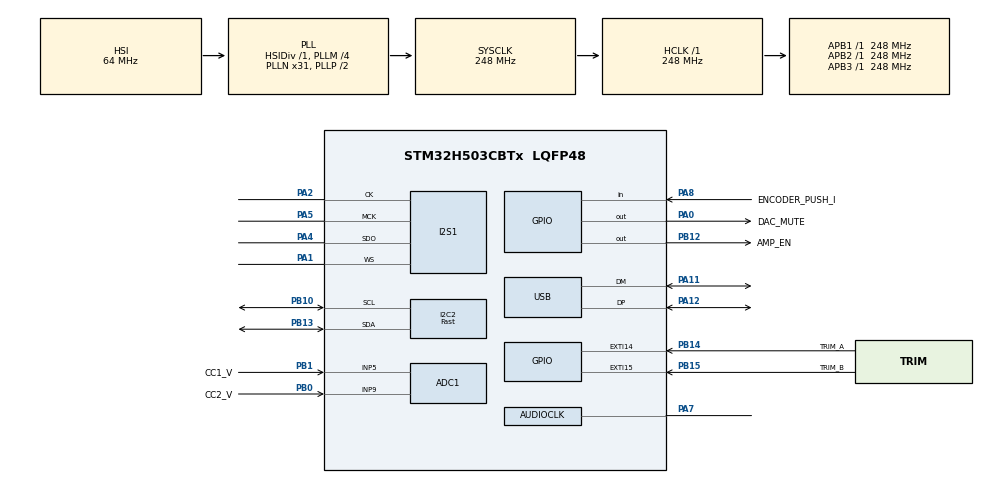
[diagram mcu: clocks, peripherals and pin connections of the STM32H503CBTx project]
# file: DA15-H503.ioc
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ADC1.Channel-1\#ChannelRegularConversion=ADC_CHANNEL_5
ADC1.Channel-2\#ChannelRegularConversion=ADC_CHANNEL_9
ADC1.MonitoredBy-1\#ChannelRegularConversion=__NULL
ADC1.MonitoredBy-2\#ChannelRegularConversion=__NULL
ADC1.NbrOfConversion=2
ADC1.NbrOfConversionFlag=1
ADC1.OffsetNumber-1\#ChannelRegularConversion=ADC_OFFSET_NONE
ADC1.OffsetNumber-2\#ChannelRegularConversion=ADC_OFFSET_NONE
ADC1.Rank-1\#ChannelRegularConversion=1
ADC1.Rank-2\#ChannelRegularConversion=2
ADC1.SamplingTime-1\#ChannelRegularConversion=ADC_SAMPLETIME_92CYCLES_5
ADC1.SamplingTime-2\#ChannelRegularConversion=ADC_SAMPLETIME_92CYCLES_5
ADC1.master=1
BOOTPATH.BootPathName=LEGACY
BOOTPATH.UserSelectedBootPath=LEGACY
CORTEX_M33_NS.AccessPermission-Cortex_Memory_Protection_Unit_Region0_Settings=MPU_REGION_ALL_RO
CORTEX_M33_NS.BaseAddress-Cortex_Memory_Protection_Unit_Region0_Settings=0x08FFF800
CORTEX_M33_NS.DisableExec-Cortex_Memory_Protection_Unit_Region0_Settings=MPU_INSTRUCTION_ACCESS_DISABLE
CORTEX_M33_NS.Enable-Cortex_Memory_Protection_Unit_Region0_Settings=MPU_REGION_ENABLE
CORTEX_M33_NS.LimitAddress-Cortex_Memory_Protection_Unit_Region0_Settings=0x08FFFFFF
CORTEX_M33_NS.MPU_Control=MPU_PRIVILEGED_DEFAULT
CORTEX_M33_NS.Memorytype0-Cortex_Memory_Protection_Unit_Attributes0_OTP_RO_AREAS_Settings=MPU_DEVICE
CORTEX_M33_NS.Number-Cortex_Memory_Protection_Unit_Region0_OTP_RO_AREAS_Settings=MPU_REGION_NUMBER0
CORTEX_M33_NS.Number-Cortex_Memory_Protection_Unit_Region0_Settings=MPU_REGION_NUMBER0
CORTEX_M33_NS.default_mode_Activation=1
GPDMA1.CIRCULARMODE_GPDMACH0=ENABLE
GPDMA1.DESTDATAWIDTH_GPDMACH0=DMA_DEST_DATAWIDTH_WORD
GPDMA1.DIRECTION_GPDMACH0=DMA_MEMORY_TO_PERIPH
GPDMA1.IPHANDLE_GPDMACH0-SIMPLEREQUEST_GPDMACH0=__NULL
GPDMA1.PRIORITY_LL_CIRCULAR_GPDMACH0=DMA_LOW_PRIORITY_HIGH_WEIGHT
GPDMA1.REQUEST_GPDMACH0=GPDMA1_REQUEST_SPI1_TX
GPDMA1.SRCDATAWIDTH_GPDMACH0=DMA_SRC_DATAWIDTH_WORD
GPDMA1.SRCINC_GPDMACH0=DMA_SINC_INCREMENTED
GPDMA2.DIRECTION_GPDMACH0=DMA_MEMORY_TO_PERIPH
GPDMA2.IPHANDLE_GPDMACH0-SIMPLEREQUEST_GPDMACH0=__NULL
GPDMA2.REQUEST_GPDMACH0=GPDMA2_REQUEST_I2C2_TX
GPDMA2.SRCINC_GPDMACH0=DMA_SINC_INCREMENTED
I2C2.I2C_Speed_Mode=I2C_Fast
I2C2.Speed=400
I2C2.Timing=0x20802C97
I2S1.AudioFreq=I2S_AUDIOFREQ_48K
I2S1.Data24BitAlignment=I2S_DATA_24BIT_ALIGNMENT_LEFT
I2S1.DataFormat=I2S_DATAFORMAT_24B
I2S1.ErrorAudioFreq=0.0 %
I2S1.Instance=SPI$Index
I2S1.RealAudioFreq=48.0 KHz
Mcu.Family=STM32H5
Mcu.Name=STM32H503CBTx
Mcu.Package=LQFP48
NVIC.EXTI14_IRQn=true\:0\:0\:false\:false\:true\:true\:true\:true
NVIC.EXTI15_IRQn=true\:0\:0\:false\:false\:true\:true\:true\:true
NVIC.GPDMA1_Channel0_IRQn=true\:0\:0\:false\:false\:true\:false\:true\:true
NVIC.GPDMA2_Channel0_IRQn=true\:0\:0\:false\:false\:true\:false\:true\:true
NVIC.I2C2_ER_IRQn=true\:0\:0\:false\:false\:true\:true\:true\:true
NVIC.I2C2_EV_IRQn=true\:0\:0\:false\:false\:true\:true\:true\:true
NVIC.PriorityGroup=NVIC_PRIORITYGROUP_4
NVIC.USB_DRD_FS_IRQn=true\:0\:0\:false\:false\:true\:true\:true\:true
PA0.GPIO_Label=DAC_MUTE
PA0.Signal=GPIO_Output
PA1.Mode=Half_Duplex_Master_Tx
PA1.Signal=I2S1_WS
PA11.Mode=Device
PA11.Signal=USB_DM
PA12.Mode=Device
PA12.Signal=USB_DP
PA2.Mode=Half_Duplex_Master_Tx
PA2.Signal=I2S1_CK
PA4.Mode=Half_Duplex_Master_Tx
PA4.Signal=I2S1_SDO
PA5.Mode=Master_Clock_Activated
PA5.Signal=I2S1_MCK
PA7.Mode=Audio_ClockInSAI1
PA7.Signal=AUDIOCLK
PA8.GPIO_Label=ENCODER_PUSH_I
PA8.Signal=GPIO_Input
PB0.GPIO_Label=CC2_V
PB0.Signal=ADCx_INP9
PB1.GPIO_Label=CC1_V
PB1.Signal=ADCx_INP5
PB10.Mode=I2C
PB10.Signal=I2C2_SCL
PB12.GPIO_Label=AMP_EN
PB12.PinState=GPIO_PIN_RESET
PB12.Signal=GPIO_Output
PB13.Mode=I2C
PB13.Signal=I2C2_SDA
PB14.GPIO_Label=TRIM_A
PB14.GPIO_ModeDefaultEXTI=GPIO_MODE_IT_RISING_FALLING
PB14.GPIO_PuPd=GPIO_PULLUP
PB14.Signal=GPXTI14
PB15.GPIO_Label=TRIM_B
PB15.GPIO_ModeDefaultEXTI=GPIO_MODE_IT_RISING_FALLING
PB15.GPIO_PuPd=GPIO_PULLUP
PB15.Signal=GPXTI15
ProjectManager.HeapSize=0x200
ProjectManager.StackSize=0x400
ProjectManager.TargetToolchain=CMake
RCC.ADCFreq_Value=248000000
RCC.AHBFreq_Value=248000000
RCC.APB1Freq_Value=248000000
RCC.APB1TimFreq_Value=248000000
RCC.APB2Freq_Value=248000000
RCC.APB2TimFreq_Value=248000000
RCC.APB3Freq_Value=248000000
RCC.CSI_VALUE=4000000
RCC.CortexFreq_Value=248000000
RCC.EPOD_VALUE=64000000
RCC.EXTERNAL_CLOCK_VALUE=24576000
RCC.HCLKFreq_Value=248000000
RCC.HSE_VALUE=25000000
RCC.HSI48_VALUE=48000000
RCC.HSIDiv=RCC_HSI_DIV1
RCC.HSI_VALUE=64000000
RCC.LSE_VALUE=32768
RCC.LSIRC_VALUE=32000
RCC.PLL2FRACN=0
RCC.PLL2P=7
RCC.PLLFRACN=0
RCC.PLLM=4
RCC.PLLN=31
RCC.PLLSourceVirtual=RCC_PLL1_SOURCE_HSI
RCC.SPI1CLockSelection=RCC_SPI1CLKSOURCE_PIN
RCC.SYSCLKFreq_VALUE=248000000
RCC.SYSCLKSource=RCC_SYSCLKSOURCE_PLLCLK
RCC.USBFreq_Value=48000000
RCC.VCOOutputFreq_Value=496000000
SH.ADCx_INP5.0=ADC1_INP5,IN5-Single-Ended
SH.ADCx_INP9.0=ADC1_INP9,IN9-Single-Ended
USB.Sof_enable-Device=DISABLE
USB.VirtualMode=Device_Only
VP_BOOTPATH_VS_BOOTPATH.Mode=BP_Activate
VP_CORTEX_M33_NS_VS_Hclk.Mode=Hclk_Mode
VP_GPDMA1_VS_GPDMACH0.Mode=SIMPLEREQUEST_GPDMACH0
VP_GPDMA2_VS_GPDMACH0.Mode=SIMPLEREQUEST_GPDMACH0
VP_ICACHE_VS_ICACHE.Mode=DefaultMode
VP_MEMORYMAP_VS_MEMORYMAP.Mode=CurAppReg
VP_PWR_VS_LPOM.Mode=PowerOptimisation
VP_PWR_VS_SECSignals.Mode=Security/Privilege
VP_RCC_USB.Mode=CRS SYNC Source USB
board=custom

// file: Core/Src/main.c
/* USER CODE BEGIN Header */
/**
  ******************************************************************************
  * @file           : main.c
  * @brief          : Main program body
  ******************************************************************************
  * @attention
  *
  * Copyright (c) 2026 STMicroelectronics.
  * All rights reserved.
  *
  * This software is licensed under terms that can be found in the LICENSE file
  * in the root directory of this software component.
  * If no LICENSE file comes with this software, it is provided AS-IS.
  *
  ******************************************************************************
  */
/* USER CODE END Header */
#include "main.h"

/* USER CODE BEGIN Includes */
#include "app.h"
#include "fault.h"
#include "SEGGER_RTT.h"
/* USER CODE END Includes */

ADC_HandleTypeDef hadc1;

I2C_HandleTypeDef hi2c2;
DMA_HandleTypeDef handle_GPDMA2_Channel0;

I2S_HandleTypeDef hi2s1;
DMA_NodeTypeDef Node_GPDMA1_Channel0;
DMA_QListTypeDef List_GPDMA1_Channel0;
DMA_HandleTypeDef handle_GPDMA1_Channel0;

PCD_HandleTypeDef hpcd_USB_DRD_FS;

void SystemClock_Config(void);
static void MPU_Config(void);
static void MX_GPIO_Init(void);
static void MX_GPDMA1_Init(void);
static void MX_GPDMA2_Init(void);
static void MX_ADC1_Init(void);
static void MX_I2C2_Init(void);
static void MX_I2S1_Init(void);
static void MX_USB_PCD_Init(void);
static void MX_ICACHE_Init(void);

int main(void)
{

  /* MCU Configuration--------------------------------------------------------*/

  /* MPU Configuration--------------------------------------------------------*/
  MPU_Config();

  /* Reset of all peripherals, Initializes the Flash interface and the Systick. */
  HAL_Init();

  /* Configure the system clock */
  SystemClock_Config();

  /* Initialize all configured peripherals */
  MX_GPIO_Init();
  MX_GPDMA1_Init();
  MX_GPDMA2_Init();
  MX_ADC1_Init();
  MX_I2C2_Init();
  MX_I2S1_Init();
  MX_USB_PCD_Init();
  MX_ICACHE_Init();
  /* USER CODE BEGIN 2 */
  app_init();
  /* USER CODE END 2 */

  /* Infinite loop */
  while (1)
  {

    /* USER CODE BEGIN 3 */
    app_loop();
  }
  /* USER CODE END 3 */
}

void SystemClock_Config(void)
{
  RCC_OscInitTypeDef RCC_OscInitStruct = {0};
  RCC_ClkInitTypeDef RCC_ClkInitStruct = {0};
  RCC_CRSInitTypeDef RCC_CRSInitStruct = {0};

  /** Configure the main internal regulator output voltage
  */
  __HAL_PWR_VOLTAGESCALING_CONFIG(PWR_REGULATOR_VOLTAGE_SCALE0);

  while(!__HAL_PWR_GET_FLAG(PWR_FLAG_VOSRDY)) {}

  /** Initializes the RCC Oscillators according to the specified parameters
  * in the RCC_OscInitTypeDef structure.
  */
  RCC_OscInitStruct.OscillatorType = RCC_OSCILLATORTYPE_HSI48|RCC_OSCILLATORTYPE_HSI;
  RCC_OscInitStruct.HSIState = RCC_HSI_ON;
  RCC_OscInitStruct.HSIDiv = RCC_HSI_DIV1;
  RCC_OscInitStruct.HSICalibrationValue = RCC_HSICALIBRATION_DEFAULT;
  RCC_OscInitStruct.HSI48State = RCC_HSI48_ON;
  RCC_OscInitStruct.PLL.PLLState = RCC_PLL_ON;
  RCC_OscInitStruct.PLL.PLLSource = RCC_PLL1_SOURCE_HSI;
  RCC_OscInitStruct.PLL.PLLM = 4;
  RCC_OscInitStruct.PLL.PLLN = 31;
  RCC_OscInitStruct.PLL.PLLP = 2;
  RCC_OscInitStruct.PLL.PLLQ = 2;
  RCC_OscInitStruct.PLL.PLLR = 2;
  RCC_OscInitStruct.PLL.PLLRGE = RCC_PLL1_VCIRANGE_3;
  RCC_OscInitStruct.PLL.PLLVCOSEL = RCC_PLL1_VCORANGE_WIDE;
  RCC_OscInitStruct.PLL.PLLFRACN = 0;
  if (HAL_RCC_OscConfig(&RCC_OscInitStruct) != HAL_OK)
  {
    Error_Handler();
  }

  /** Initializes the CPU, AHB and APB buses clocks
  */
  RCC_ClkInitStruct.ClockType = RCC_CLOCKTYPE_HCLK|RCC_CLOCKTYPE_SYSCLK
                              |RCC_CLOCKTYPE_PCLK1|RCC_CLOCKTYPE_PCLK2
                              |RCC_CLOCKTYPE_PCLK3;
  RCC_ClkInitStruct.SYSCLKSource = RCC_SYSCLKSOURCE_PLLCLK;
  RCC_ClkInitStruct.AHBCLKDivider = RCC_SYSCLK_DIV1;
  RCC_ClkInitStruct.APB1CLKDivider = RCC_HCLK_DIV1;
  RCC_ClkInitStruct.APB2CLKDivider = RCC_HCLK_DIV1;
  RCC_ClkInitStruct.APB3CLKDivider = RCC_HCLK_DIV1;

  if (HAL_RCC_ClockConfig(&RCC_ClkInitStruct, FLASH_LATENCY_5) != HAL_OK)
  {
    Error_Handler();
  }

  /** Enable the CRS APB clock
  */
  __HAL_RCC_CRS_CLK_ENABLE();

  /** Configures CRS
  */
  RCC_CRSInitStruct.Prescaler = RCC_CRS_SYNC_DIV1;
  RCC_CRSInitStruct.Source = RCC_CRS_SYNC_SOURCE_USB;
  RCC_CRSInitStruct.Polarity = RCC_CRS_SYNC_POLARITY_RISING;
  RCC_CRSInitStruct.ReloadValue = __HAL_RCC_CRS_RELOADVALUE_CALCULATE(48000000,1000);
  RCC_CRSInitStruct.ErrorLimitValue = 34;
  RCC_CRSInitStruct.HSI48CalibrationValue = 32;

  HAL_RCCEx_CRSConfig(&RCC_CRSInitStruct);

  /** Configure the programming delay
  */
  __HAL_FLASH_SET_PROGRAM_DELAY(FLASH_PROGRAMMING_DELAY_2);
}

static void MX_ADC1_Init(void)
{

  ADC_ChannelConfTypeDef sConfig = {0};

  /** Common config
  */
  hadc1.Instance = ADC1;
  hadc1.Init.ClockPrescaler = ADC_CLOCK_ASYNC_DIV8;
  hadc1.Init.Resolution = ADC_RESOLUTION_12B;
  hadc1.Init.DataAlign = ADC_DATAALIGN_RIGHT;
  hadc1.Init.ScanConvMode = ADC_SCAN_ENABLE;
  hadc1.Init.EOCSelection = ADC_EOC_SINGLE_CONV;
  hadc1.Init.LowPowerAutoWait = DISABLE;
  hadc1.Init.ContinuousConvMode = DISABLE;
  hadc1.Init.NbrOfConversion = 2;
  hadc1.Init.DiscontinuousConvMode = DISABLE;
  hadc1.Init.ExternalTrigConv = ADC_SOFTWARE_START;
  hadc1.Init.ExternalTrigConvEdge = ADC_EXTERNALTRIGCONVEDGE_NONE;
  hadc1.Init.DMAContinuousRequests = DISABLE;
  hadc1.Init.SamplingMode = ADC_SAMPLING_MODE_NORMAL;
  hadc1.Init.Overrun = ADC_OVR_DATA_PRESERVED;
  hadc1.Init.OversamplingMode = DISABLE;
  if (HAL_ADC_Init(&hadc1) != HAL_OK)
  {
    Error_Handler();
  }

  /** Configure Regular Channel
  */
  sConfig.Channel = ADC_CHANNEL_5;
  sConfig.Rank = ADC_REGULAR_RANK_1;
  sConfig.SamplingTime = ADC_SAMPLETIME_92CYCLES_5;
  sConfig.SingleDiff = ADC_SINGLE_ENDED;
  sConfig.OffsetNumber = ADC_OFFSET_NONE;
  sConfig.Offset = 0;
  if (HAL_ADC_ConfigChannel(&hadc1, &sConfig) != HAL_OK)
  {
    Error_Handler();
  }

  /** Configure Regular Channel
  */
  sConfig.Channel = ADC_CHANNEL_9;
  sConfig.Rank = ADC_REGULAR_RANK_2;
  if (HAL_ADC_ConfigChannel(&hadc1, &sConfig) != HAL_OK)
  {
    Error_Handler();
  }

}

static void MX_GPDMA1_Init(void)
{

  /* Peripheral clock enable */
  __HAL_RCC_GPDMA1_CLK_ENABLE();

  /* GPDMA1 interrupt Init */
    HAL_NVIC_SetPriority(GPDMA1_Channel0_IRQn, 0, 0);
    HAL_NVIC_EnableIRQ(GPDMA1_Channel0_IRQn);

}

static void MX_GPDMA2_Init(void)
{

  /* Peripheral clock enable */
  __HAL_RCC_GPDMA2_CLK_ENABLE();

  /* GPDMA2 interrupt Init */
    HAL_NVIC_SetPriority(GPDMA2_Channel0_IRQn, 0, 0);
    HAL_NVIC_EnableIRQ(GPDMA2_Channel0_IRQn);

}

static void MX_I2C2_Init(void)
{

  hi2c2.Instance = I2C2;
  hi2c2.Init.Timing = 0x20802C97;
  hi2c2.Init.OwnAddress1 = 0;
  hi2c2.Init.AddressingMode = I2C_ADDRESSINGMODE_7BIT;
  hi2c2.Init.DualAddressMode = I2C_DUALADDRESS_DISABLE;
  hi2c2.Init.OwnAddress2 = 0;
  hi2c2.Init.OwnAddress2Masks = I2C_OA2_NOMASK;
  hi2c2.Init.GeneralCallMode = I2C_GENERALCALL_DISABLE;
  hi2c2.Init.NoStretchMode = I2C_NOSTRETCH_DISABLE;
  if (HAL_I2C_Init(&hi2c2) != HAL_OK)
  {
    Error_Handler();
  }

  /** Configure Analogue filter
  */
  if (HAL_I2CEx_ConfigAnalogFilter(&hi2c2, I2C_ANALOGFILTER_ENABLE) != HAL_OK)
  {
    Error_Handler();
  }

  /** Configure Digital filter
  */
  if (HAL_I2CEx_ConfigDigitalFilter(&hi2c2, 0) != HAL_OK)
  {
    Error_Handler();
  }

}

static void MX_I2S1_Init(void)
{

  hi2s1.Instance = SPI1;
  hi2s1.Init.Mode = I2S_MODE_MASTER_TX;
  hi2s1.Init.Standard = I2S_STANDARD_PHILIPS;
  hi2s1.Init.DataFormat = I2S_DATAFORMAT_24B;
  hi2s1.Init.MCLKOutput = I2S_MCLKOUTPUT_ENABLE;
  hi2s1.Init.AudioFreq = I2S_AUDIOFREQ_48K;
  hi2s1.Init.CPOL = I2S_CPOL_LOW;
  hi2s1.Init.FirstBit = I2S_FIRSTBIT_MSB;
  hi2s1.Init.WSInversion = I2S_WS_INVERSION_DISABLE;
  hi2s1.Init.Data24BitAlignment = I2S_DATA_24BIT_ALIGNMENT_LEFT;
  hi2s1.Init.MasterKeepIOState = I2S_MASTER_KEEP_IO_STATE_DISABLE;
  if (HAL_I2S_Init(&hi2s1) != HAL_OK)
  {
    Error_Handler();
  }

}

static void MX_ICACHE_Init(void)
{

  /** Enable instruction cache (default 2-ways set associative cache)
  */
  if (HAL_ICACHE_Enable() != HAL_OK)
  {
    Error_Handler();
  }

}

static void MX_USB_PCD_Init(void)
{

  hpcd_USB_DRD_FS.Instance = USB_DRD_FS;
  hpcd_USB_DRD_FS.Init.dev_endpoints = 8;
  hpcd_USB_DRD_FS.Init.speed = USBD_FS_SPEED;
  hpcd_USB_DRD_FS.Init.phy_itface = PCD_PHY_EMBEDDED;
  hpcd_USB_DRD_FS.Init.Sof_enable = DISABLE;
  hpcd_USB_DRD_FS.Init.low_power_enable = DISABLE;
  hpcd_USB_DRD_FS.Init.lpm_enable = DISABLE;
  hpcd_USB_DRD_FS.Init.battery_charging_enable = DISABLE;
  hpcd_USB_DRD_FS.Init.vbus_sensing_enable = DISABLE;
  hpcd_USB_DRD_FS.Init.bulk_doublebuffer_enable = DISABLE;
  hpcd_USB_DRD_FS.Init.iso_singlebuffer_enable = DISABLE;
  if (HAL_PCD_Init(&hpcd_USB_DRD_FS) != HAL_OK)
  {
    Error_Handler();
  }

}

static void MX_GPIO_Init(void)
{
  GPIO_InitTypeDef GPIO_InitStruct = {0};

  /* GPIO Ports Clock Enable */
  __HAL_RCC_GPIOA_CLK_ENABLE();
  __HAL_RCC_GPIOB_CLK_ENABLE();

  /*Configure GPIO pin Output Level */
  HAL_GPIO_WritePin(DAC_MUTE_GPIO_Port, DAC_MUTE_Pin, GPIO_PIN_RESET);

  /*Configure GPIO pin Output Level */
  HAL_GPIO_WritePin(AMP_EN_GPIO_Port, AMP_EN_Pin, GPIO_PIN_RESET);

  /*Configure GPIO pin : DAC_MUTE_Pin */
  GPIO_InitStruct.Pin = DAC_MUTE_Pin;
  GPIO_InitStruct.Mode = GPIO_MODE_OUTPUT_PP;
  GPIO_InitStruct.Pull = GPIO_NOPULL;
  GPIO_InitStruct.Speed = GPIO_SPEED_FREQ_LOW;
  HAL_GPIO_Init(DAC_MUTE_GPIO_Port, &GPIO_InitStruct);

  /*Configure GPIO pin : PA7 */
  GPIO_InitStruct.Pin = GPIO_PIN_7;
  GPIO_InitStruct.Mode = GPIO_MODE_AF_PP;
  GPIO_InitStruct.Pull = GPIO_NOPULL;
  GPIO_InitStruct.Speed = GPIO_SPEED_FREQ_LOW;
  GPIO_InitStruct.Alternate = GPIO_AF7_SPI2;
  HAL_GPIO_Init(GPIOA, &GPIO_InitStruct);

  /*Configure GPIO pin : AMP_EN_Pin */
  GPIO_InitStruct.Pin = AMP_EN_Pin;
  GPIO_InitStruct.Mode = GPIO_MODE_OUTPUT_PP;
  GPIO_InitStruct.Pull = GPIO_NOPULL;
  GPIO_InitStruct.Speed = GPIO_SPEED_FREQ_LOW;
  HAL_GPIO_Init(AMP_EN_GPIO_Port, &GPIO_InitStruct);

  /*Configure GPIO pins : TRIM_A_Pin TRIM_B_Pin */
  GPIO_InitStruct.Pin = TRIM_A_Pin|TRIM_B_Pin;
  GPIO_InitStruct.Mode = GPIO_MODE_IT_RISING_FALLING;
  GPIO_InitStruct.Pull = GPIO_PULLUP;
  HAL_GPIO_Init(GPIOB, &GPIO_InitStruct);

  /*Configure GPIO pin : ENCODER_PUSH_I_Pin */
  GPIO_InitStruct.Pin = ENCODER_PUSH_I_Pin;
  GPIO_InitStruct.Mode = GPIO_MODE_INPUT;
  GPIO_InitStruct.Pull = GPIO_NOPULL;
  HAL_GPIO_Init(ENCODER_PUSH_I_GPIO_Port, &GPIO_InitStruct);

  /* EXTI interrupt init*/
  HAL_NVIC_SetPriority(EXTI14_IRQn, 0, 0);
  HAL_NVIC_EnableIRQ(EXTI14_IRQn);

  HAL_NVIC_SetPriority(EXTI15_IRQn, 0, 0);
  HAL_NVIC_EnableIRQ(EXTI15_IRQn);

}

 /* MPU Configuration */

void MPU_Config(void)
{
  MPU_Region_InitTypeDef MPU_InitStruct = {0};
  MPU_Attributes_InitTypeDef MPU_AttributesInit = {0};

  /* Disables the MPU */
  HAL_MPU_Disable();

  /** Initializes and configures the Region 0 and the memory to be protected
  */
  MPU_InitStruct.Enable = MPU_REGION_ENABLE;
  MPU_InitStruct.Number = MPU_REGION_NUMBER0;
  MPU_InitStruct.BaseAddress = 0x08FFF000;
  MPU_InitStruct.LimitAddress = 0x08FFFFFF;
  MPU_InitStruct.AttributesIndex = MPU_ATTRIBUTES_NUMBER0;
  MPU_InitStruct.AccessPermission = MPU_REGION_ALL_RO;
  MPU_InitStruct.DisableExec = MPU_INSTRUCTION_ACCESS_DISABLE;
  MPU_InitStruct.IsShareable = MPU_ACCESS_NOT_SHAREABLE;

  HAL_MPU_ConfigRegion(&MPU_InitStruct);

  /** Initializes and configures the Attribute 0 and the memory to be protected
  */
  MPU_AttributesInit.Number = MPU_ATTRIBUTES_NUMBER0;
  MPU_AttributesInit.Attributes = MPU_DEVICE_nGnRnE;

  HAL_MPU_ConfigMemoryAttributes(&MPU_AttributesInit);
  /* Enables the MPU */
  HAL_MPU_Enable(MPU_PRIVILEGED_DEFAULT);

}

void Error_Handler(void)
{
  /* USER CODE BEGIN Error_Handler_Debug */
  /* User can add his own implementation to report the HAL error return state */
  app_fault_safe_state(); /* mute DAC + amp off; IWDG resets us if running */
  fault_capture(FAULT_ERROR_HANDLER);
  __disable_irq();
  while (1)
  {
  }
  /* USER CODE END Error_Handler_Debug */
}
